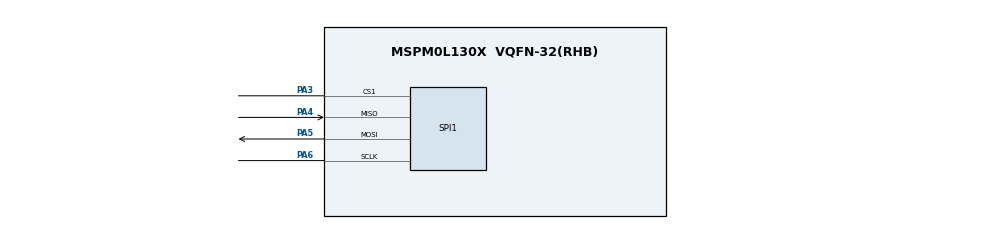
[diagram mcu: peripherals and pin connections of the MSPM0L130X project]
/**
 * @cliArgs --device "MSPM0L130X" --package "VQFN-32(RHB)" --part "Default" --product "mspm0_sdk@1.00.01.03"
 * @versions {"tool":"1.16.1+2960"}
 */

/**
 * Import the modules used in this configuration.
 */
const ADC12  = scripting.addModule("/ti/driverlib/ADC12", {}, false);
const ADC121 = ADC12.addInstance();
const GPIO   = scripting.addModule("/ti/driverlib/GPIO", {}, false);
const GPIO1  = GPIO.addInstance();
const SPI    = scripting.addModule("/ti/driverlib/SPI", {}, false);
const SPI1   = SPI.addInstance();
const TIMER  = scripting.addModule("/ti/driverlib/TIMER", {}, false);
const TIMER1 = TIMER.addInstance();

/**
 * Write custom configuration values to the imported modules.
 */
ADC121.$name             = "ADC";
ADC121.sampClkDiv        = "DL_ADC12_CLOCK_DIVIDE_4";
ADC121.repeatMode        = true;
ADC121.trigSrc           = "DL_ADC12_TRIG_SRC_EVENT";
ADC121.adcMem0chansel    = "DL_ADC12_INPUT_CHAN_7";
ADC121.sampleTime0       = "3.25 us";
ADC121.enabledInterrupts = ["DL_ADC12_INTERRUPT_MEM0_RESULT_LOADED"];
ADC121.subChanID         = 1;

const Board = scripting.addModule("/ti/driverlib/Board", {}, false);

GPIO1.$name                         = "GPIO_LEDS";
GPIO1.associatedPins[0].$name       = "USER_LED_1";
GPIO1.associatedPins[0].assignedPin = "0";

SPI1.$name                                 = "SPI_0";
SPI1.mode                                  = "PERIPHERAL";
SPI1.rxFifoThreshold                       = "DL_SPI_RX_FIFO_LEVEL_ONE_FRAME";
SPI1.txFifoThreshold                       = "DL_SPI_TX_FIFO_LEVEL_ONE_FRAME";
SPI1.enabledDMAEvent1Triggers              = "DL_SPI_DMA_INTERRUPT_RX";
SPI1.enabledInterrupts                     = ["DMA_DONE_RX"];
SPI1.peripheralChipSelect                  = "1";
SPI1.clearRXCounterOnCSIdle                = true;
SPI1.peripheral.$assign                    = "SPI0";
SPI1.peripheral.sclkPin.$assign            = "PA6";
SPI1.peripheral.mosiPin.$assign            = "PA5";
SPI1.peripheral.misoPin.$assign            = "PA4";
SPI1.peripheral.cs1Pin.$assign             = "PA3";
SPI1.sclkPinConfig.$name                   = "ti_driverlib_gpio_GPIOPinGeneric0";
SPI1.mosiPinConfig.$name                   = "ti_driverlib_gpio_GPIOPinGeneric1";
SPI1.mosiPinConfig.hideOutputInversion     = scripting.forceWrite(false);
SPI1.misoPinConfig.$name                   = "ti_driverlib_gpio_GPIOPinGeneric2";
SPI1.DMA_CHANNEL_EVENT1.$name              = "DMA_CH0";
SPI1.DMA_CHANNEL_EVENT1.addressMode        = "f2b";
SPI1.DMA_CHANNEL_EVENT1.srcLength          = "BYTE";
SPI1.DMA_CHANNEL_EVENT1.dstLength          = "BYTE";
SPI1.DMA_CHANNEL_EVENT1.peripheral.$assign = "DMA_CH0";
SPI1.cs1PinConfig.$name                    = "ti_driverlib_gpio_GPIOPinGeneric3";

const SYSCTL = scripting.addModule("/ti/driverlib/SYSCTL", {}, false);

TIMER1.$name                       = "TIMER_ADC";
TIMER1.timerClkSrc                 = "LFCLK";
TIMER1.timerMode                   = "PERIODIC";
TIMER1.event1PublisherChannel      = 1;
TIMER1.event1ControllerInterruptEn = ["ZERO_EVENT"];
TIMER1.timerPeriod                 = "10 ms";

/**
 * Pinmux solution for unlocked pins/peripherals. This ensures that minor changes to the automatic solver in a future
 * version of the tool will not impact the pinmux you originally saw.  These lines can be completely deleted in order to
 * re-solve from scratch.
 */
ADC121.peripheral.$suggestSolution           = "ADC0";
ADC121.peripheral.adcPin7.$suggestSolution   = "PA18";
Board.peripheral.$suggestSolution            = "DEBUGSS";
Board.peripheral.swclkPin.$suggestSolution   = "PA20";
Board.peripheral.swdioPin.$suggestSolution   = "PA19";
GPIO1.associatedPins[0].pin.$suggestSolution = "PA0";
SYSCTL.peripheral.$suggestSolution           = "SYSCTL";
TIMER1.peripheral.$suggestSolution           = "TIMG0";
